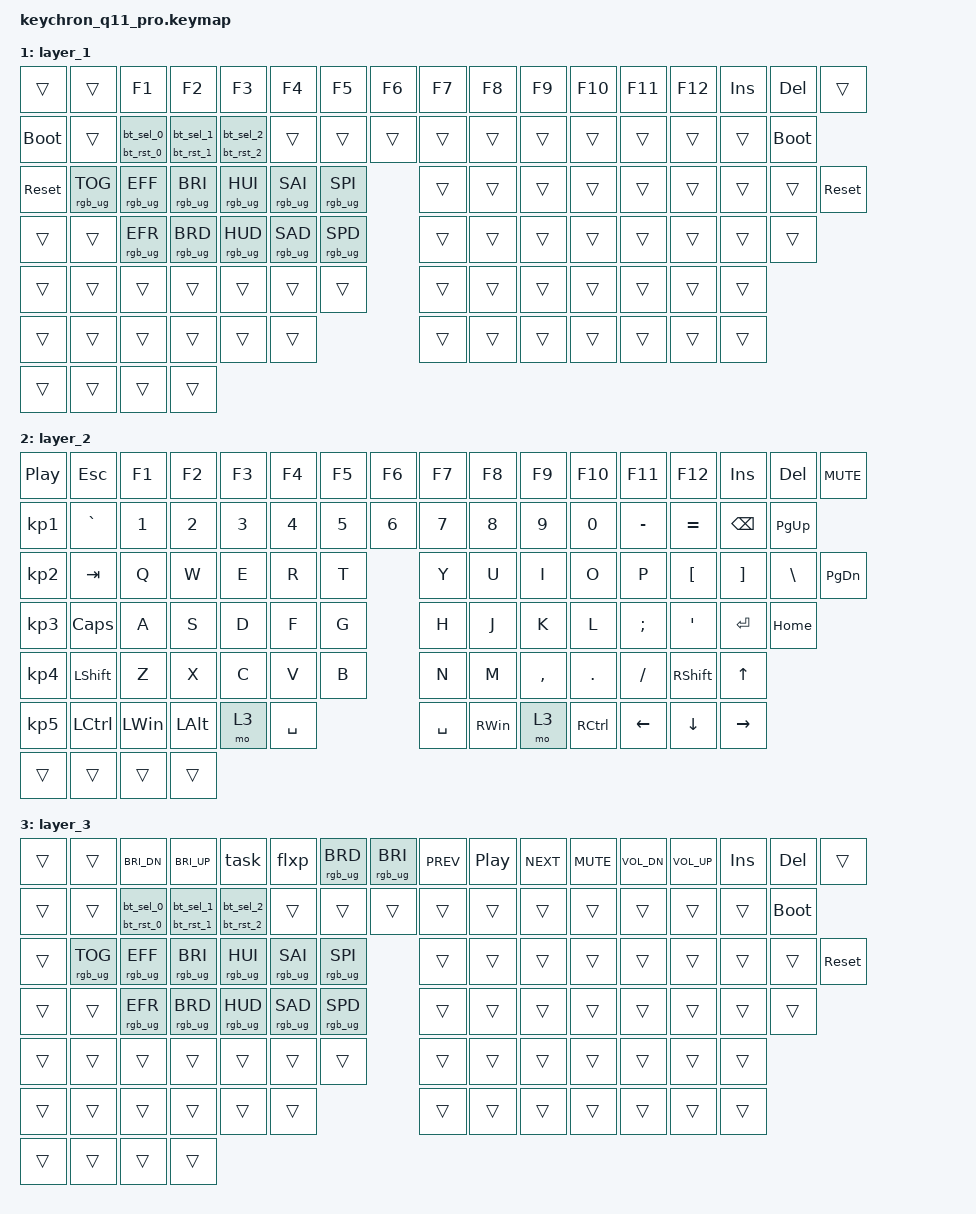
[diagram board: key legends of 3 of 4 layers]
/*
 * Copyright (c) 2024 Byran Huang, Keychron
 *
 * SPDX-License-Identifier: MIT
 */

#include <behaviors.dtsi>
#include <dt-bindings/zmk/keys.h>
#include <dt-bindings/zmk/rgb.h>
#include <dt-bindings/zmk/bt.h>
#include <dt-bindings/zmk/outputs.h>
#include <dt-bindings/zmk/ext_power.h>

/ {
    behaviors {
        bt_ht_0: bt_ht_0 {
            compatible = "zmk,behavior-hold-tap";
            label = "HOLD_TAP_BT_0";
            #binding-cells = <2>;
            tapping-term-ms = <3000>;
            flavor = "hold-preferred";
            bindings = <&bt_rst_0>, <&bt_sel_0>;
        };
        bt_ht_1: bt_ht_1 {
            compatible = "zmk,behavior-hold-tap";
            label = "HOLD_TAP_BT_1";
            #binding-cells = <2>;
            tapping-term-ms = <3000>;
            flavor = "hold-preferred";
            bindings = <&bt_rst_1>, <&bt_sel_1>; };
        bt_ht_2: bt_ht_2 {
            compatible = "zmk,behavior-hold-tap";
            label = "HOLD_TAP_BT_2";
            #binding-cells = <2>;
            tapping-term-ms = <3000>;
            flavor = "hold-preferred";
            bindings = <&bt_rst_2>, <&bt_sel_2>;
        };
    };
    macros {
        task: task {
            label = "TASK_VIEW";
            compatible = "zmk,behavior-macro";
            #binding-cells = <0>;
            bindings
                = <&macro_press &kp LWIN>
                , <&macro_tap &kp TAB>
                , <&macro_release &kp LWIN>
                ;
        };
        flxp: flxp {
            label = "FILE_EXPLORER";
            compatible = "zmk,behavior-macro";
            #binding-cells = <0>;
            bindings
                = <&macro_press &kp LWIN>
                , <&macro_tap &kp E>
                , <&macro_release &kp LWIN>
                ;
        };
        bt_sel_0: bt_sel_0 {
            label = "SELECT_BT_0";
            compatible = "zmk,behavior-macro";
            #binding-cells = <0>;
            bindings
                = <&macro_tap &bt BT_SEL 0>
                ;
        };
        bt_sel_1: bt_sel_1 {
            label = "SELECT_BT_1";
            compatible = "zmk,behavior-macro";
            #binding-cells = <0>;
            bindings
                = <&macro_tap &bt BT_SEL 1>
                ;
        };
        bt_sel_2: bt_sel_2 {
            label = "SELECT_BT_2";
            compatible = "zmk,behavior-macro";
            #binding-cells = <0>;
            bindings
                = <&macro_tap &bt BT_SEL 2>
                ;
        };
        // Using BT_SEL 4 to ensure bluetooth is fully reset
        bt_rst_0: bt_rst_0 {
            label = "RESET_BT_0";
            compatible = "zmk,behavior-macro";
            #binding-cells = <0>;
            bindings
                = <&macro_tap &bt BT_SEL 4>
                , <&macro_tap &bt BT_CLR>
                , <&macro_tap &bt BT_SEL 0>
                , <&macro_tap &bt BT_CLR>
                ;
        };
        bt_rst_1: bt_rst_1 {
            label = "RESET_BT_1";
            compatible = "zmk,behavior-macro";
            #binding-cells = <0>;
            bindings
                = <&macro_tap &bt BT_SEL 4>
                , <&macro_tap &bt BT_CLR>
                , <&macro_tap &bt BT_SEL 1>
                , <&macro_tap &bt BT_CLR>
                ;
        };
        bt_rst_2: bt_rst_2 {
            label = "RESET_BT_2";
            compatible = "zmk,behavior-macro";
            #binding-cells = <0>;
            bindings
                = <&macro_tap &bt BT_SEL 4>
                , <&macro_tap &bt BT_CLR>
                , <&macro_tap &bt BT_SEL 2>
                , <&macro_tap &bt BT_CLR>
                ;
        };
    };
    keymap {
        compatible = "zmk,keymap";

        // mac
        layer_0 {
            bindings = <
            &kp C_PLAY_PAUSE    &kp ESC          &kp C_BRI_DN       &kp C_BRI_UP       &kp C_AC_DESKTOP_SHOW_ALL_WINDOWS       &kp C_AC_DESKTOP_SHOW_ALL_APPLICATIONS       &rgb_ug RGB_BRD       &rgb_ug RGB_BRI /**/  &kp C_PREV              &kp C_PP              &kp C_NEXT              &kp C_MUTE             &kp C_VOL_DN             &kp C_VOL_UP             &kp INS             &kp DEL             &kp C_MUTE
            &kp KP_N1           &kp GRAVE        &kp N1       &kp N2       &kp N3       &kp N4       &kp N5       &kp N6 /**/  &kp N7              &kp N8              &kp N9              &kp N0              &kp MINUS           &kp EQUAL           &kp BSPC            &kp PG_UP
            &kp KP_N2           &kp TAB          &kp Q        &kp W        &kp E        &kp R                     &kp T /**/   &kp Y        &kp U               &kp I               &kp O               &kp P               &kp LBKT            &kp RBKT            &kp BSLH            &kp PG_DN
            &kp KP_N3           &kp CAPS         &kp A        &kp S        &kp D        &kp F                     &kp G /**/   &kp H        &kp J               &kp K               &kp L               &kp SEMI            &kp SQT             &kp RET             &kp HOME
            &kp KP_N4           &kp LSHIFT       &kp Z        &kp X        &kp C        &kp V                     &kp B /**/   &kp N        &kp M               &kp COMMA           &kp PERIOD          &kp FSLH            &kp RSHIFT          &kp UP
            &kp KP_N5           &kp LCTRL        &kp LALT     &kp LCMD     &mo 1        &kp SPACE                       /**/   &kp SPACE    &kp RCMD            &mo 1               &kp RCTRL           &kp LEFT            &kp DOWN            &kp RIGHT
            &mo 2
            >;
            sensor-bindings = <&inc_dec_kp C_VOL_DN C_VOL_UP &inc_dec_kp C_BRI_DN C_BRI_UP>;
        };
        layer_1 {
            bindings = <
            &trans              &trans           &kp F1          &kp F2          &kp F3          &kp F4          &kp F5       &kp F6/**/       &kp F7              &kp F8              &kp F9              &kp F10             &kp F11             &kp F12             &kp INS             &kp DEL             &trans
            &bootloader         &trans           &bt_ht_0 0 0    &bt_ht_1 0 0    &bt_ht_2 0 0    &trans          &trans       &trans      /**/ &trans              &trans              &trans              &trans              &trans              &trans              &trans              &bootloader
            &sys_reset          &rgb_ug RGB_TOG  &rgb_ug RGB_EFF &rgb_ug RGB_BRI &rgb_ug RGB_HUI &rgb_ug RGB_SAI &rgb_ug RGB_SPI    /**/       &trans              &trans              &trans              &trans              &trans              &trans              &trans              &trans              &sys_reset
            &trans              &trans           &rgb_ug RGB_EFR &rgb_ug RGB_BRD &rgb_ug RGB_HUD &rgb_ug RGB_SAD &rgb_ug RGB_SPD               &trans              &trans              &trans              &trans              &trans              &trans              &trans              &trans
            &trans              &trans           &trans          &trans          &trans          &trans          &trans                        &trans              &trans              &trans              &trans              &trans              &trans              &trans
            &trans              &trans           &trans          &trans          &trans          &trans                                        &trans              &trans              &trans              &trans              &trans              &trans              &trans
            &trans              &trans           &trans          &trans
            >;
            sensor-bindings = <&inc_dec_kp C_VOL_DN C_VOL_UP &inc_dec_kp C_BRI_DN C_BRI_UP>;
        };
        // win
        layer_2 {
            bindings = <
            &kp C_PLAY_PAUSE    &kp ESC          &kp F1          &kp F2          &kp F3          &kp F4          &kp F5       &kp F6/**/    &kp F7              &kp F8              &kp F9              &kp F10             &kp F11             &kp F12             &kp INS             &kp DEL             &kp C_MUTE
            &kp KP_N1           &kp GRAVE        &kp N1       &kp N2       &kp N3       &kp N4       &kp N5       &kp N6 /**/  &kp N7              &kp N8              &kp N9              &kp N0              &kp MINUS           &kp EQUAL           &kp BSPC            &kp PG_UP
            &kp KP_N2           &kp TAB          &kp Q        &kp W        &kp E        &kp R                     &kp T /**/   &kp Y        &kp U               &kp I               &kp O               &kp P               &kp LBKT            &kp RBKT            &kp BSLH            &kp PG_DN
            &kp KP_N3           &kp CAPS         &kp A        &kp S        &kp D        &kp F                     &kp G /**/   &kp H        &kp J               &kp K               &kp L               &kp SEMI            &kp SQT             &kp RET             &kp HOME
            &kp KP_N4           &kp LSHIFT       &kp Z        &kp X        &kp C        &kp V                     &kp B /**/   &kp N        &kp M               &kp COMMA           &kp PERIOD          &kp FSLH            &kp RSHIFT          &kp UP
            &kp KP_N5           &kp LCTRL        &kp LWIN     &kp LALT     &mo 3        &kp SPACE                       /**/   &kp SPACE    &kp RWIN            &mo 3               &kp RCTRL           &kp LEFT            &kp DOWN            &kp RIGHT
            &trans              &trans           &trans       &trans
            >;
            sensor-bindings = <&inc_dec_kp C_VOL_DN C_VOL_UP &inc_dec_kp C_BRI_DN C_BRI_UP>;
        };
        layer_3 {
            bindings = <
            &trans              &trans           &kp C_BRI_DN          &kp C_BRI_UP          &task          &flxp           &rgb_ug RGB_BRD      &rgb_ug RGB_BRI /**/   &kp C_PREV              &kp C_PP              &kp C_NEXT              &kp C_MUTE             &kp C_VOL_DN             &kp C_VOL_UP             &kp INS             &kp DEL             &trans
            &trans              &trans           &bt_ht_0 0 0    &bt_ht_1 0 0    &bt_ht_2 0 0    &trans          &trans       &trans      /**/ &trans              &trans              &trans              &trans              &trans              &trans              &trans              &bootloader
            &trans              &rgb_ug RGB_TOG  &rgb_ug RGB_EFF &rgb_ug RGB_BRI &rgb_ug RGB_HUI &rgb_ug RGB_SAI &rgb_ug RGB_SPI    /**/       &trans              &trans              &trans              &trans              &trans              &trans              &trans              &trans              &sys_reset
            &trans              &trans           &rgb_ug RGB_EFR &rgb_ug RGB_BRD &rgb_ug RGB_HUD &rgb_ug RGB_SAD &rgb_ug RGB_SPD               &trans              &trans              &trans              &trans              &trans              &trans              &trans              &trans
            &trans              &trans           &trans          &trans          &trans          &trans          &trans                        &trans              &trans              &trans              &trans              &trans              &trans              &trans
            &trans              &trans           &trans          &trans          &trans          &trans                                        &trans              &trans              &trans              &trans              &trans              &trans              &trans
            &trans              &trans           &trans          &trans
            >;
            sensor-bindings = <&inc_dec_kp C_VOL_DN C_VOL_UP &inc_dec_kp C_BRI_DN C_BRI_UP>;
        };
    };
};
